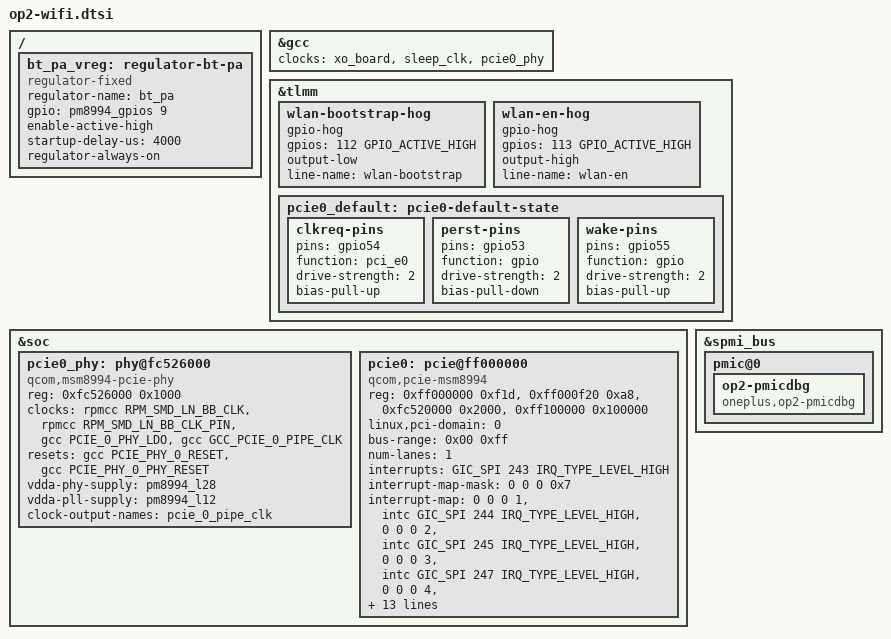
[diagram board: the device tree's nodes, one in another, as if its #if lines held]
// SPDX-License-Identifier: GPL-2.0
/*
 * OnePlus 2 (DTS_DEFINES=OP2_WIFI): Wi-Fi of the QCA6174 combo on PCIe.
 * Default (no OP2_WIFI_PCIE1): PCIe0 (PARF 0xfc520000, PHY 0xfc526000),
 * as the CAF msm8994.dtsi pcie0 node suggests. With OP2_WIFI_PCIE1: PCIe1
 * (PARF 0xfc528000, PHY 0xfc52e000, DBI 0xf8800000, PERST gpio 35, WAKE 37,
 * CLKREQ gpio 36, MSI 271, scm-dev-id 12) — the RC the stock DTBs enable
 * (pcie0 disabled, pcie1 okay in all 13 stock DTBs) and cnss wlan-rc-num=1
 * points to. Default off: OP2_WIFI_PCIE1 is not defined.
 *
 * From the OnePlus kernel (msm8994.dtsi:811-887 pcie0, :3586-3593 cnss):
 * PARF 0xfc520000, PHY 0xfc526000, DBI 0xff000000, ELBI 0xff000f20, config
 * 0xff100000, I/O 0xff200000, memory 0xff300000 (13 MiB); MSI SPI 243, INTA-D
 * SPI 244/245/247/248; PERST GPIO 53, CLKREQ 54 (pci_e0), WAKE 55; supplies
 * L12 1.8 V + L28 0.9 V, GDSC pcie_0; TZ scm-dev-id 11. The chip itself:
 * vdd-wlan = PM8994 GPIO 9 (also the BT PA supply), io S4, xtal L30, WL_EN
 * GPIO 113. Patches 0019 (PHY) and 0020 (controller). Driver: ath10k_pci,
 * firmware ath10k/QCA6174/hw3.0 from linux-firmware.
 */

/ {
#ifndef OP2_BT
	/* chip power (OnePlus bt_vreg = vdd-wlan), shared with op2-bt.dtsi */
	bt_pa_vreg: regulator-bt-pa {
		compatible = "regulator-fixed";
		regulator-name = "bt_pa";
		gpio = <&pm8994_gpios 9 GPIO_ACTIVE_HIGH>;
		enable-active-high;
		startup-delay-us = <4000>;
		regulator-always-on;
	};
#endif
};

/* GCC's pcie_0_pipe_clk_src takes the PHY's pipe output (patch 0021) */
&gcc {
#ifndef OP2_WIFI_PCIE1
	clock-names = "xo", "sleep", "pcie_0_pipe";
	clocks = <&xo_board>, <&sleep_clk>, <&pcie0_phy>;
#else
	clock-names = "xo", "sleep", "pcie_1_pipe";
	clocks = <&xo_board>, <&sleep_clk>, <&pcie1_phy>;
#endif
};

&tlmm {
#if defined(OP2_WIFI_BOOT) || defined(OP2_WIFI_BOOTLOW)
	/* stock cnss wlan-bootstrap-gpio (tlmm 112): chip strapping, set before WL_EN */
	wlan-bootstrap-hog {
		gpio-hog;
		gpios = <112 GPIO_ACTIVE_HIGH>;
#ifdef OP2_WIFI_BOOTLOW
		output-low;
#else
		output-high;
#endif
		line-name = "wlan-bootstrap";
	};
#endif

	/* WL_EN: the Wi-Fi half of the chip out of reset */
	wlan-en-hog {
		gpio-hog;
		gpios = <113 GPIO_ACTIVE_HIGH>;
		output-high;
		line-name = "wlan-en";
	};

#ifndef OP2_WIFI_PCIE1
	pcie0_default: pcie0-default-state {
		clkreq-pins {
			pins = "gpio54";
			function = "pci_e0";
			drive-strength = <2>;
			bias-pull-up;
		};
		perst-pins {
			pins = "gpio53";
			function = "gpio";
			drive-strength = <2>;
			bias-pull-down;
		};
		wake-pins {
			pins = "gpio55";
			function = "gpio";
			drive-strength = <2>;
			bias-pull-up;
		};
	};
#else
	/* stock DT pcie1 pinctrl: clkreq gpio36 func pci_e1, perst gpio35,
	 * wake gpio37 (op2-hw14.dtb pcie1_clkreq/perst/wake) */
	pcie1_default: pcie1-default-state {
		clkreq-pins {
			pins = "gpio36";
			function = "pci_e1";
			drive-strength = <2>;
			bias-pull-up;
		};
		perst-pins {
			pins = "gpio35";
			function = "gpio";
			drive-strength = <2>;
			bias-pull-down;
		};
		wake-pins {
			pins = "gpio37";
			function = "gpio";
			drive-strength = <2>;
			bias-pull-up;
		};
	};
#endif
};

&soc {
#ifndef OP2_WIFI_PCIE1
	pcie0_phy: phy@fc526000 {
		compatible = "qcom,msm8994-pcie-phy";	/* patch 0019 */
		reg = <0xfc526000 0x1000>;
#ifdef OP2_WIFI_REFPIN
		clocks = <&rpmcc RPM_SMD_LN_BB_CLK>,
			 <&rpmcc RPM_SMD_LN_BB_CLK_PIN>,
			 <&gcc PCIE_0_PHY_LDO>,
			 <&gcc GCC_PCIE_0_PIPE_CLK>;
		clock-names = "ref", "ref_pin", "ldo", "pipe";
#else
		clocks = <&rpmcc RPM_SMD_LN_BB_CLK>,
			 <&gcc PCIE_0_PHY_LDO>,
			 <&gcc GCC_PCIE_0_PIPE_CLK>;
		clock-names = "ref", "ldo", "pipe";
#endif
#ifdef OP2_WIFI_PIPE_RESET
		/* retry of s63 now that the aux clock runs (patch 0028) */
		resets = <&gcc PCIE_PHY_0_RESET>, <&gcc PCIE_PHY_0_PHY_RESET>;
		reset-names = "phy", "pipe";
#else
		resets = <&gcc PCIE_PHY_0_RESET>;
		reset-names = "phy";
#endif
		/*
		 * CAF also deasserts PCIE_PHY_0_PHY_BCR (0x1B14, still asserted
		 * after boot) before the pipe clock. Passing it here as
		 * <&gcc PCIE_PHY_0_PHY_RESET> "pipe" (patch 0022) reset the
		 * phone at boot (s63, s64 without ath10k): off until understood.
		 */
		vdda-phy-supply = <&pm8994_l28>;
		vdda-pll-supply = <&pm8994_l12>;
		#phy-cells = <0>;
		/* the 125 MHz pipe clock it feeds GCC (patches 0019, 0021) */
		#clock-cells = <0>;
		clock-output-names = "pcie_0_pipe_clk";
	};

	pcie0: pcie@ff000000 {
		compatible = "qcom,pcie-msm8994";	/* patch 0020 */
		reg = <0xff000000 0xf1d>,
		      <0xff000f20 0xa8>,
		      <0xfc520000 0x2000>,
		      <0xff100000 0x100000>;
		reg-names = "dbi", "elbi", "parf", "config";
		device_type = "pci";
		linux,pci-domain = <0>;
		bus-range = <0x00 0xff>;
		num-lanes = <1>;
		#address-cells = <3>;
		#size-cells = <2>;
		ranges = <0x81000000 0x0 0x0 0xff200000 0x0 0x100000>,
			 <0x82000000 0x0 0xff300000 0xff300000 0x0 0xd00000>;

		interrupts = <GIC_SPI 243 IRQ_TYPE_LEVEL_HIGH>;
		interrupt-names = "msi";
		#interrupt-cells = <1>;
		interrupt-map-mask = <0 0 0 0x7>;
		interrupt-map = <0 0 0 1 &intc GIC_SPI 244 IRQ_TYPE_LEVEL_HIGH>,
				<0 0 0 2 &intc GIC_SPI 245 IRQ_TYPE_LEVEL_HIGH>,
				<0 0 0 3 &intc GIC_SPI 247 IRQ_TYPE_LEVEL_HIGH>,
				<0 0 0 4 &intc GIC_SPI 248 IRQ_TYPE_LEVEL_HIGH>;

		/* CAF msm8994.dtsi:872-881 also feeds the host the 125 MHz pipe
		 * clock (pcie_0_pipe_clk); the DWC core enables it via bulk */
		clocks = <&gcc GCC_PCIE_0_PIPE_CLK>,
			 <&gcc GCC_PCIE_0_CFG_AHB_CLK>,
			 <&gcc GCC_PCIE_0_MSTR_AXI_CLK>,
			 <&gcc GCC_PCIE_0_SLV_AXI_CLK>,
			 <&gcc GCC_PCIE_0_AUX_CLK>;
		clock-names = "pipe", "iface", "master_bus", "slave_bus", "aux";
		/*
		 * CAF runs the aux clock at 1.01 MHz: set by patch 0020 in init, with
		 * the GDSC on (patch 0027 makes the rate settable). Not assigned-clocks:
		 * set at device creation, with the GDSC off, the branch stayed off (s89).
		 */
		power-domains = <&gcc PCIE_0_GDSC>;
		vdda-supply = <&pm8994_l28>;

		phys = <&pcie0_phy>;
		phy-names = "pciephy";

		perst-gpios = <&tlmm 53 GPIO_ACTIVE_LOW>;
		wake-gpios = <&tlmm 55 GPIO_ACTIVE_HIGH>;
		pinctrl-names = "default";
		pinctrl-0 = <&pcie0_default>;

		qcom,scm-dev-id = <11>;
	};
#else
	/* PCIe1 = RC1: the root complex the stock OnePlus 2 DTBs enable and
	 * cnss qcom,wlan-rc-num=1 points to (PARF 0xfc528000, PHY
	 * 0xfc52e000, DBI 0xf8800000, ELBI 0xf8800f20, config 0xf8801000,
	 * io 0xf8880000, bars 0xf8900000; stock op2-hw14.dtb
	 * qcom,pcie@fc528000). IRQs SPI 271-282, PERST gpio 35, WAKE 37,
	 * scm-dev-id 12, GDSC pcie_1 (gcc 0x1b44), BCRs 0x1b98/0x1b94. */
	pcie1_phy: phy@fc52e000 {
		compatible = "qcom,msm8994-pcie-phy";	/* patch 0019 */
		reg = <0xfc52e000 0x1000>;
#ifdef OP2_WIFI_REFPIN
		clocks = <&rpmcc RPM_SMD_LN_BB_CLK>,
			 <&rpmcc RPM_SMD_LN_BB_CLK_PIN>,
			 <&gcc PCIE_1_PHY_LDO>,
			 <&gcc GCC_PCIE_1_PIPE_CLK>;
		clock-names = "ref", "ref_pin", "ldo", "pipe";
#else
		clocks = <&rpmcc RPM_SMD_LN_BB_CLK>,
			 <&gcc PCIE_1_PHY_LDO>,
			 <&gcc GCC_PCIE_1_PIPE_CLK>;
		clock-names = "ref", "ldo", "pipe";
#endif
#ifdef OP2_WIFI_PIPE_RESET
		resets = <&gcc PCIE_PHY_1_RESET>, <&gcc PCIE_PHY_1_PHY_RESET>;
		reset-names = "phy", "pipe";
#else
		resets = <&gcc PCIE_PHY_1_RESET>;
		reset-names = "phy";
#endif
		vdda-phy-supply = <&pm8994_l28>;
		vdda-pll-supply = <&pm8994_l12>;
		#phy-cells = <0>;
		#clock-cells = <0>;
		clock-output-names = "pcie_1_pipe_clk";
	};

	pcie1: pcie@f8800000 {
		compatible = "qcom,pcie-msm8994";	/* patch 0020 */
		reg = <0xf8800000 0xf1d>,
		      <0xf8800f20 0xa8>,
		      <0xfc528000 0x2000>,
		      <0xf8801000 0x7f000>;
		reg-names = "dbi", "elbi", "parf", "config";
		device_type = "pci";
		linux,pci-domain = <1>;
		bus-range = <0x00 0xff>;
		num-lanes = <1>;
		#address-cells = <3>;
		#size-cells = <2>;
		ranges = <0x81000000 0x0 0x0 0xf8880000 0x0 0x80000>,
			 <0x82000000 0x0 0xf8900000 0xf8900000 0x0 0x700000>;

		interrupts = <GIC_SPI 271 IRQ_TYPE_LEVEL_HIGH>;
		interrupt-names = "msi";
		#interrupt-cells = <1>;
		interrupt-map-mask = <0 0 0 0x7>;
		interrupt-map = <0 0 0 1 &intc GIC_SPI 272 IRQ_TYPE_LEVEL_HIGH>,
				<0 0 0 2 &intc GIC_SPI 273 IRQ_TYPE_LEVEL_HIGH>,
				<0 0 0 3 &intc GIC_SPI 274 IRQ_TYPE_LEVEL_HIGH>,
				<0 0 0 4 &intc GIC_SPI 275 IRQ_TYPE_LEVEL_HIGH>;

		clocks = <&gcc GCC_PCIE_1_PIPE_CLK>,
			 <&gcc GCC_PCIE_1_CFG_AHB_CLK>,
			 <&gcc GCC_PCIE_1_MSTR_AXI_CLK>,
			 <&gcc GCC_PCIE_1_SLV_AXI_CLK>,
			 <&gcc GCC_PCIE_1_AUX_CLK>;
		clock-names = "pipe", "iface", "master_bus", "slave_bus", "aux";
		power-domains = <&gcc PCIE_1_GDSC>;
		vdda-supply = <&pm8994_l28>;

		phys = <&pcie1_phy>;
		phy-names = "pciephy";

		perst-gpios = <&tlmm 35 GPIO_ACTIVE_LOW>;
		wake-gpios = <&tlmm 37 GPIO_ACTIVE_HIGH>;
		pinctrl-names = "default";
		pinctrl-0 = <&pcie1_default>;

		qcom,scm-dev-id = <12>;
	};
#endif
};

/* Read-only PM8994 register dump (patch 0152) to check the LN_BB clock buffer */
&spmi_bus {
	pmic@0 {
		op2-pmicdbg {
			compatible = "oneplus,op2-pmicdbg";
		};
	};
};
